# MPU_0 register map
Vendor: Texas Instruments
Peripheral module from a debugger description file (folder 66AK2G0x_66AK2G1x).
Registers are 32-bit, access per field, reset 0x0 unless marked. A register's access mark holds for its fields unless they carry their own. Offsets are as the file gives them; lines under a group give offsets from that group; [hi:lo] are bit positions; {n}, {i} and the like mark numbered series; 'fields as' and 'values as' point back to an identical list; <NAME> marks a mode.

## MPU_0
0x00 MPU_REVID ro reset 0x4E814901
  [31:0] REV — TI internal data. Identifies revision of peripheral.
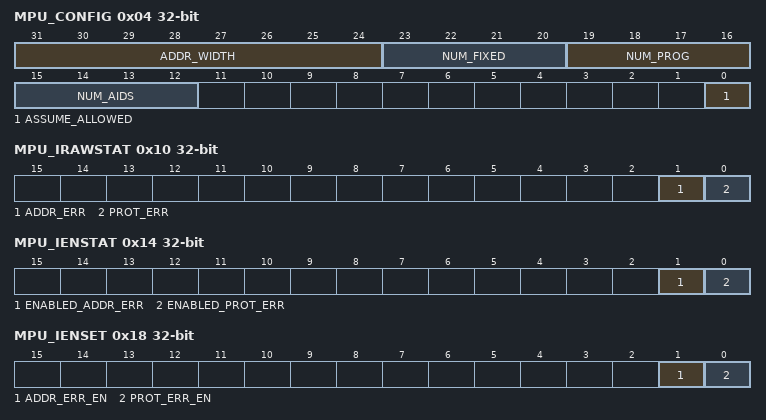
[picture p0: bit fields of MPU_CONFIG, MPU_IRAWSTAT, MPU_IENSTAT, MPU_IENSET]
0x04 MPU_CONFIG ro (reset mask 0xFFE)
  [31:24] ADDR_WIDTH — Address alignment for range checking. 0 = 1 KB alignment 1 = 2 KB alignment ... 6 = 64 KB alignment
  [23:20] NUM_FIXED — Shows the number of fixed address ranges supproted by the corresponding MPU. 0 = 0 fixed address ranges supproted 1 = 1 fixed address range supproted 2 = 2 fixed address ranges supproted ... F = 15 fixed address ranges
  [19:16] NUM_PROG — Shows the number of programmable address ranges supproted by the corresponding MPU. 0 = 16 programmable address ranges 1 = 1 programmable address range 2 = 2 programmable address ranges 3 = 3 programmable address ranges ... F = 15 programmable address ranges
  [15:12] NUM_AIDS — Shows the number of supported AIDs. 0 = 16 supported AIDs 1 = 1 supported AID 2 = 2 supported AIDs 3 = 3 supported AIDs ... F = 15 supported AIDs
  [0] ASSUME_ALLOWED — Assume allowed bit. When an address is not covered by any MPU protection range, this bit determines whether the transfer is assumed to be allowed or not. 0 = Assume disallowed 1 = Assume allowed
0x10 MPU_IRAWSTAT
  [1] ADDR_ERR rw — Addressing violation error. Raw status is read.
  [0] PROT_ERR rw — Protection violation error. Raw status is read.
0x14 MPU_IENSTAT
  [1] ENABLED_ADDR_ERR rw — Addressing violation error. Enabled status is read.
  [0] ENABLED_PROT_ERR rw — Protection violation error. Enabled status is read.
0x18 MPU_IENSET
  [1] ADDR_ERR_EN rw — Addressing violation error enable.
  [0] PROT_ERR_EN rw — Protection violation error enable.
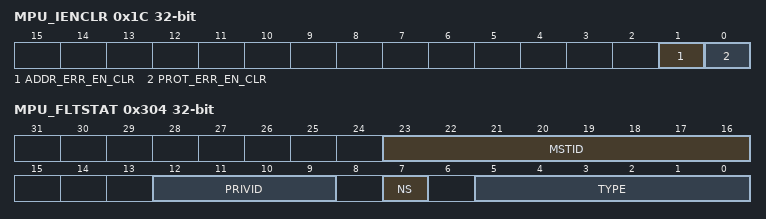
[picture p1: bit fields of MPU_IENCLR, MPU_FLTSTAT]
0x1C MPU_IENCLR
  [1] ADDR_ERR_EN_CLR rw — Addressing violation error enable.
  [0] PROT_ERR_EN_CLR rw — Protection violation error enable.
0x20 MPU_EOI
  [7:0] EOI_VECTOR rw — MPU_EOI vector value. Write this with the interrupt distribution value in the device. This drives the mpu_eoi_vector output signal. MPU_EOI Value is 0 for MPU.
0x300 MPU_FLTADDRR ro
  [31:0] ADDR — Memory address of fault.
0x304 MPU_FLTSTAT ro
  [23:16] MSTID — Master ID of fault transfer.
  [12:9] PRIVID — Privilege ID of fault transfer.
  [7] NS — Security level of fault transfer.
  [5:0] TYPE — Fault type.
0x308 MPU_FLTCLR
  [0] CLEAR wo — Command to clear the current fault. Writing 0 has no effect.
